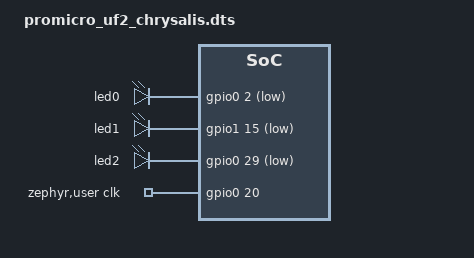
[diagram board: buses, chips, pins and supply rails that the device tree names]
// Copyright (c) 2024 Nordic Semiconductor ASA
// SPDX-License-Identifier: Apache-2.0

/dts-v1/;
#include "promicro_uf2.dts"

&pwm0_default {
	group1 {
		psels = <NRF_PSEL(PWM_OUT0, 0, 2)>, // Red
				<NRF_PSEL(PWM_OUT1, 1, 15)>, // Green
				<NRF_PSEL(PWM_OUT2, 0, 29)>; // Blue
		nordic,drive-mode = <NRF_DRIVE_S0S1>;
		nordic,invert;
	};
};

&pwm0_sleep {
	group1 {
		psels = <NRF_PSEL(PWM_OUT0, 0, 2)>, // Red
				<NRF_PSEL(PWM_OUT1, 1, 15)>, // Green
				<NRF_PSEL(PWM_OUT2, 0, 29)>; // Blue
		low-power-enable;
	};
};

/ {
	pwmleds {
		/delete-node/ pwm_led_0;
		pwm_led0: pwm_led_0 {
			pwms = <&pwm0 0 PWM_MSEC(1) PWM_POLARITY_INVERTED>; // Red
		};
		pwm_led1: pwm_led_1 {
			pwms = <&pwm0 1 PWM_MSEC(1) PWM_POLARITY_INVERTED>; // Green
		};
		pwm_led2: pwm_led_2 {
			pwms = <&pwm0 2 PWM_MSEC(1) PWM_POLARITY_INVERTED>; // Blue
		};
	};

	leds {
		compatible = "gpio-leds";
		led0: led_0 {
			gpios = <&gpio0 2 GPIO_ACTIVE_LOW>; // Red
		};
		led1: led_1 {
			gpios = <&gpio1 15 GPIO_ACTIVE_LOW>; // Green
		};
		led2: led_2 {
			gpios = <&gpio0 29 GPIO_ACTIVE_LOW>; // Blue
		};
	};

	aliases {
		sw0 = &button0;
		pwm-led0 = &pwm_led0; // Red
		pwm-led1 = &pwm_led1; // Green
		pwm-led2 = &pwm_led2; // Blue
		led0 = &led0; // Red
		led1 = &led1; // Green
		led2 = &led2; // Blue
	};

	zephyr,user {
		clk-gpios = <&gpio0 20 GPIO_OPEN_DRAIN>;
		/delete-property/ led-gpios;
	};
};

/delete-node/ &i2c0;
